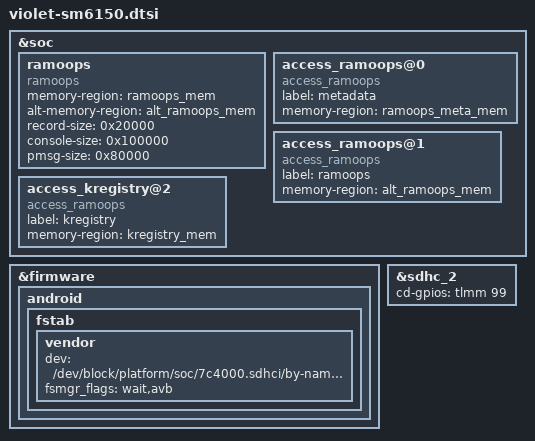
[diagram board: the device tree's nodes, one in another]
/* Copyright (c) 2020, The Linux Foundation. All rights reserved.
 *
 * This program is free software; you can redistribute it and/or modify
 * it under the terms of the GNU General Public License version 2 and
 * only version 2 as published by the Free Software Foundation.
 *
 * This program is distributed in the hope that it will be useful,
 * but WITHOUT ANY WARRANTY; without even the implied warranty of
 * MERCHANTABILITY or FITNESS FOR A PARTICULAR PURPOSE.  See the
 * GNU General Public License for more details.
 */

#include "../qcom-base/sm6150-idp.dtsi"
#include "violet-sm6150-audio.dtsi"
#include "violet-sm6150-battery.dtsi"
#include "violet-sm6150-camera.dtsi"
#include "violet-sm6150-display.dtsi"
#include "violet-sm6150-fingerprint.dtsi"
#include "violet-sm6150-ir.dtsi"
#include "violet-sm6150-memory.dtsi"
#include "violet-sm6150-nfc.dtsi"
#include "violet-sm6150-pinctrl.dtsi"
#include "violet-sm6150-pm6150.dtsi"
#include "violet-sm6150-pm6150l.dtsi"
#include "violet-sm6150-regulator.dtsi"
#include "violet-sm6150-thermal.dtsi"
#include "violet-sm6150-touchscreen.dtsi"

&soc {
	ramoops {
		compatible = "ramoops";
		memory-region = <&ramoops_mem>;
		alt-memory-region = <&alt_ramoops_mem>;
		record-size = <0x20000>;
		console-size = <0x100000>;
		pmsg-size = <0x80000>;
	};

	access_ramoops@0 {
		compatible = "access_ramoops";
		label = "metadata";
		memory-region = <&ramoops_meta_mem>;
	};

	access_ramoops@1 {
		compatible = "access_ramoops";
		label = "ramoops";
		memory-region = <&alt_ramoops_mem>;
	};

	access_kregistry@2 {
		compatible = "access_ramoops";
		label = "kregistry";
		memory-region = <&kregistry_mem>;
	};
};

&firmware {
	android {
		fstab {
			vendor {
				dev = "/dev/block/platform/soc/7c4000.sdhci/by-name/vendor";
				fsmgr_flags = "wait,avb";
			};
		};
	};
};

&sdhc_2 {
	cd-gpios = <&tlmm 99 0>;
};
